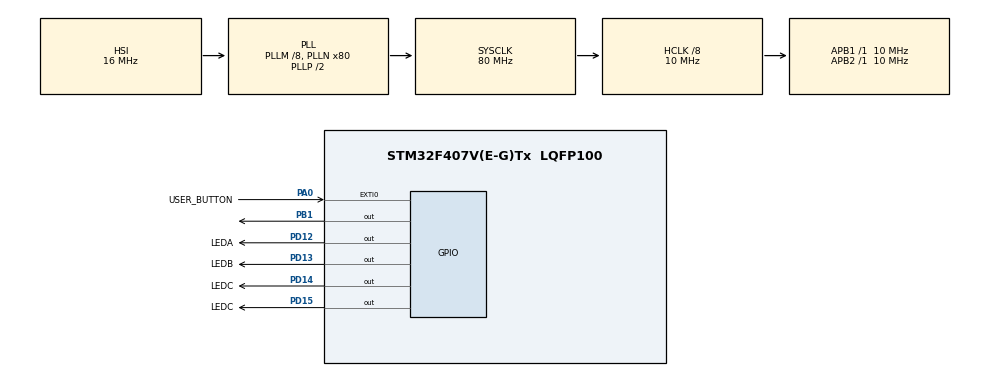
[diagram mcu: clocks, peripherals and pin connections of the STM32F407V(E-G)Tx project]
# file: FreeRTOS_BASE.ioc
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Mcu.Family=STM32F4
Mcu.Name=STM32F407V(E-G)Tx
Mcu.Package=LQFP100
NVIC.EXTI0_IRQn=true\:0\:0\:false\:false\:true\:true\:true\:true
NVIC.PriorityGroup=NVIC_PRIORITYGROUP_4
NVIC.TIM1_UP_TIM10_IRQn=true\:15\:0\:false\:false\:true\:false\:true\:true
NVIC.TIM2_IRQn=true\:0\:0\:false\:false\:true\:true\:true\:true
NVIC.TimeBase=TIM1_UP_TIM10_IRQn
NVIC.TimeBaseIP=TIM1
PA0-WKUP.GPIO_Label=USER_BUTTON
PA0-WKUP.Signal=GPXTI0
PB1.Signal=GPIO_Output
PD12.GPIO_Label=LEDA
PD12.Signal=GPIO_Output
PD13.GPIO_Label=LEDB
PD13.Signal=GPIO_Output
PD14.GPIO_Label=LEDC
PD14.Signal=GPIO_Output
PD15.GPIO_Label=LEDC
PD15.Signal=GPIO_Output
ProjectManager.HeapSize=0x200
ProjectManager.StackSize=0x400
ProjectManager.TargetToolchain=Makefile
RCC.48MHZClocksFreq_Value=40000000
RCC.AHBCLKDivider=RCC_SYSCLK_DIV8
RCC.AHBFreq_Value=10000000
RCC.APB1Freq_Value=10000000
RCC.APB1TimFreq_Value=10000000
RCC.APB2Freq_Value=10000000
RCC.APB2TimFreq_Value=10000000
RCC.CortexFreq_Value=10000000
RCC.HCLKFreq_Value=10000000
RCC.HSE_VALUE=25000000
RCC.HSI_VALUE=16000000
RCC.LSE_VALUE=32768
RCC.PLLM=8
RCC.PLLN=80
RCC.SYSCLKFreq_VALUE=80000000
RCC.SYSCLKSource=RCC_SYSCLKSOURCE_PLLCLK
RCC.VCOOutputFreq_Value=160000000
TIM2.Period=1000
TIM2.Prescaler=10000
VP_SYS_VS_tim1.Mode=TIM1
VP_TIM2_VS_ClockSourceINT.Mode=Internal
board=custom

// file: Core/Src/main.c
/* USER CODE BEGIN Header */
/**
  ******************************************************************************
  * @file           : main.c
  * @brief          : Main program body
  ******************************************************************************
  * @attention
  *
  * Copyright (c) 2024 STMicroelectronics.
  * All rights reserved.
  *
  * This software is licensed under terms that can be found in the LICENSE file
  * in the root directory of this software component.
  * If no LICENSE file comes with this software, it is provided AS-IS.
  *
  ******************************************************************************
  */
/* USER CODE END Header */
#include "main.h"
#include "FreeRTOS.h"
#include "task.h"

/* USER CODE BEGIN PM */

 void vApplicationMallocFailedHook( void ){
// Turn ON led to Fatal ERROR

 }

void vApplicationStackOverflowHook(struct tskTaskControlBlock *, char *){
// Turn ON led to Fatal ERROR

}
/* USER CODE END PM */

TIM_HandleTypeDef htim2;

/* USER CODE BEGIN PV */

void task1(void* args){

  for( ;; )
  {
    HAL_GPIO_TogglePin(GPIOD,LEDB_Pin);
    vTaskDelay(500/portTICK_PERIOD_MS);
  }
}

/* USER CODE END PV */

void SystemClock_Config(void);
static void MX_GPIO_Init(void);
static void MX_TIM2_Init(void);

int main(void)
{

  /* MCU Configuration--------------------------------------------------------*/

  /* Reset of all peripherals, Initializes the Flash interface and the Systick. */
  HAL_Init();

  /* Configure the system clock */
  SystemClock_Config();

  /* Initialize all configured peripherals */
  MX_GPIO_Init();
  MX_TIM2_Init();
  /* USER CODE BEGIN 2 */

  TaskHandle_t t1 ;

  xTaskCreate(task1,"Task 1 Example",2000,NULL,0,&t1);

  /* USER CODE END 2 */

  /* Infinite loop */
  /* USER CODE BEGIN WHILE */

  vTaskStartScheduler();
  uint8_t value = 0;
  while (1)
  {
    value = HAL_GPIO_ReadPin(GPIOA,USER_BUTTON_Pin) ;
    if(value)    HAL_GPIO_WritePin(GPIOD,LEDA_Pin,1);
    HAL_Delay(2000);
    HAL_GPIO_WritePin(GPIOD,LEDA_Pin,0);
    HAL_GPIO_TogglePin(GPIOD,LEDC_Pin);
    /* USER CODE END WHILE */

  }
}

void SystemClock_Config(void)
{
  RCC_OscInitTypeDef RCC_OscInitStruct = {0};
  RCC_ClkInitTypeDef RCC_ClkInitStruct = {0};

  /** Configure the main internal regulator output voltage
  */
  __HAL_RCC_PWR_CLK_ENABLE();
  __HAL_PWR_VOLTAGESCALING_CONFIG(PWR_REGULATOR_VOLTAGE_SCALE1);

  /** Initializes the RCC Oscillators according to the specified parameters
  * in the RCC_OscInitTypeDef structure.
  */
  RCC_OscInitStruct.OscillatorType = RCC_OSCILLATORTYPE_HSI;
  RCC_OscInitStruct.HSIState = RCC_HSI_ON;
  RCC_OscInitStruct.HSICalibrationValue = RCC_HSICALIBRATION_DEFAULT;
  RCC_OscInitStruct.PLL.PLLState = RCC_PLL_ON;
  RCC_OscInitStruct.PLL.PLLSource = RCC_PLLSOURCE_HSI;
  RCC_OscInitStruct.PLL.PLLM = 8;
  RCC_OscInitStruct.PLL.PLLN = 80;
  RCC_OscInitStruct.PLL.PLLP = RCC_PLLP_DIV2;
  RCC_OscInitStruct.PLL.PLLQ = 4;
  if (HAL_RCC_OscConfig(&RCC_OscInitStruct) != HAL_OK)
  {
    Error_Handler();
  }

  /** Initializes the CPU, AHB and APB buses clocks
  */
  RCC_ClkInitStruct.ClockType = RCC_CLOCKTYPE_HCLK|RCC_CLOCKTYPE_SYSCLK
                              |RCC_CLOCKTYPE_PCLK1|RCC_CLOCKTYPE_PCLK2;
  RCC_ClkInitStruct.SYSCLKSource = RCC_SYSCLKSOURCE_PLLCLK;
  RCC_ClkInitStruct.AHBCLKDivider = RCC_SYSCLK_DIV8;
  RCC_ClkInitStruct.APB1CLKDivider = RCC_HCLK_DIV1;
  RCC_ClkInitStruct.APB2CLKDivider = RCC_HCLK_DIV1;

  if (HAL_RCC_ClockConfig(&RCC_ClkInitStruct, FLASH_LATENCY_0) != HAL_OK)
  {
    Error_Handler();
  }
}

static void MX_TIM2_Init(void)
{

  TIM_ClockConfigTypeDef sClockSourceConfig = {0};
  TIM_MasterConfigTypeDef sMasterConfig = {0};

  htim2.Instance = TIM2;
  htim2.Init.Prescaler = 10000;
  htim2.Init.CounterMode = TIM_COUNTERMODE_UP;
  htim2.Init.Period = 1000;
  htim2.Init.ClockDivision = TIM_CLOCKDIVISION_DIV1;
  htim2.Init.AutoReloadPreload = TIM_AUTORELOAD_PRELOAD_DISABLE;
  if (HAL_TIM_Base_Init(&htim2) != HAL_OK)
  {
    Error_Handler();
  }
  sClockSourceConfig.ClockSource = TIM_CLOCKSOURCE_INTERNAL;
  if (HAL_TIM_ConfigClockSource(&htim2, &sClockSourceConfig) != HAL_OK)
  {
    Error_Handler();
  }
  sMasterConfig.MasterOutputTrigger = TIM_TRGO_RESET;
  sMasterConfig.MasterSlaveMode = TIM_MASTERSLAVEMODE_DISABLE;
  if (HAL_TIMEx_MasterConfigSynchronization(&htim2, &sMasterConfig) != HAL_OK)
  {
    Error_Handler();
  }

}

static void MX_GPIO_Init(void)
{
  GPIO_InitTypeDef GPIO_InitStruct = {0};

  /* GPIO Ports Clock Enable */
  __HAL_RCC_GPIOA_CLK_ENABLE();
  __HAL_RCC_GPIOB_CLK_ENABLE();
  __HAL_RCC_GPIOD_CLK_ENABLE();

  /*Configure GPIO pin Output Level */
  HAL_GPIO_WritePin(GPIOB, GPIO_PIN_1, GPIO_PIN_RESET);

  /*Configure GPIO pin Output Level */
  HAL_GPIO_WritePin(GPIOD, LEDA_Pin|LEDB_Pin|LEDC_Pin|LEDCD15_Pin, GPIO_PIN_RESET);

  /*Configure GPIO pin : USER_BUTTON_Pin */
  GPIO_InitStruct.Pin = USER_BUTTON_Pin;
  GPIO_InitStruct.Mode = GPIO_MODE_IT_RISING;
  GPIO_InitStruct.Pull = GPIO_NOPULL;
  HAL_GPIO_Init(USER_BUTTON_GPIO_Port, &GPIO_InitStruct);

  /*Configure GPIO pin : PB1 */
  GPIO_InitStruct.Pin = GPIO_PIN_1;
  GPIO_InitStruct.Mode = GPIO_MODE_OUTPUT_PP;
  GPIO_InitStruct.Pull = GPIO_NOPULL;
  GPIO_InitStruct.Speed = GPIO_SPEED_FREQ_LOW;
  HAL_GPIO_Init(GPIOB, &GPIO_InitStruct);

  /*Configure GPIO pins : LEDA_Pin LEDB_Pin LEDC_Pin LEDCD15_Pin */
  GPIO_InitStruct.Pin = LEDA_Pin|LEDB_Pin|LEDC_Pin|LEDCD15_Pin;
  GPIO_InitStruct.Mode = GPIO_MODE_OUTPUT_PP;
  GPIO_InitStruct.Pull = GPIO_NOPULL;
  GPIO_InitStruct.Speed = GPIO_SPEED_FREQ_LOW;
  HAL_GPIO_Init(GPIOD, &GPIO_InitStruct);

  /* EXTI interrupt init*/
  HAL_NVIC_SetPriority(EXTI0_IRQn, 0, 0);
  HAL_NVIC_EnableIRQ(EXTI0_IRQn);

}

void HAL_TIM_PeriodElapsedCallback(TIM_HandleTypeDef *htim)
{
  if (htim->Instance == TIM1) {
    HAL_IncTick();
  }
}

void Error_Handler(void)
{
  __disable_irq();
  while (1)
  {
  }
}
